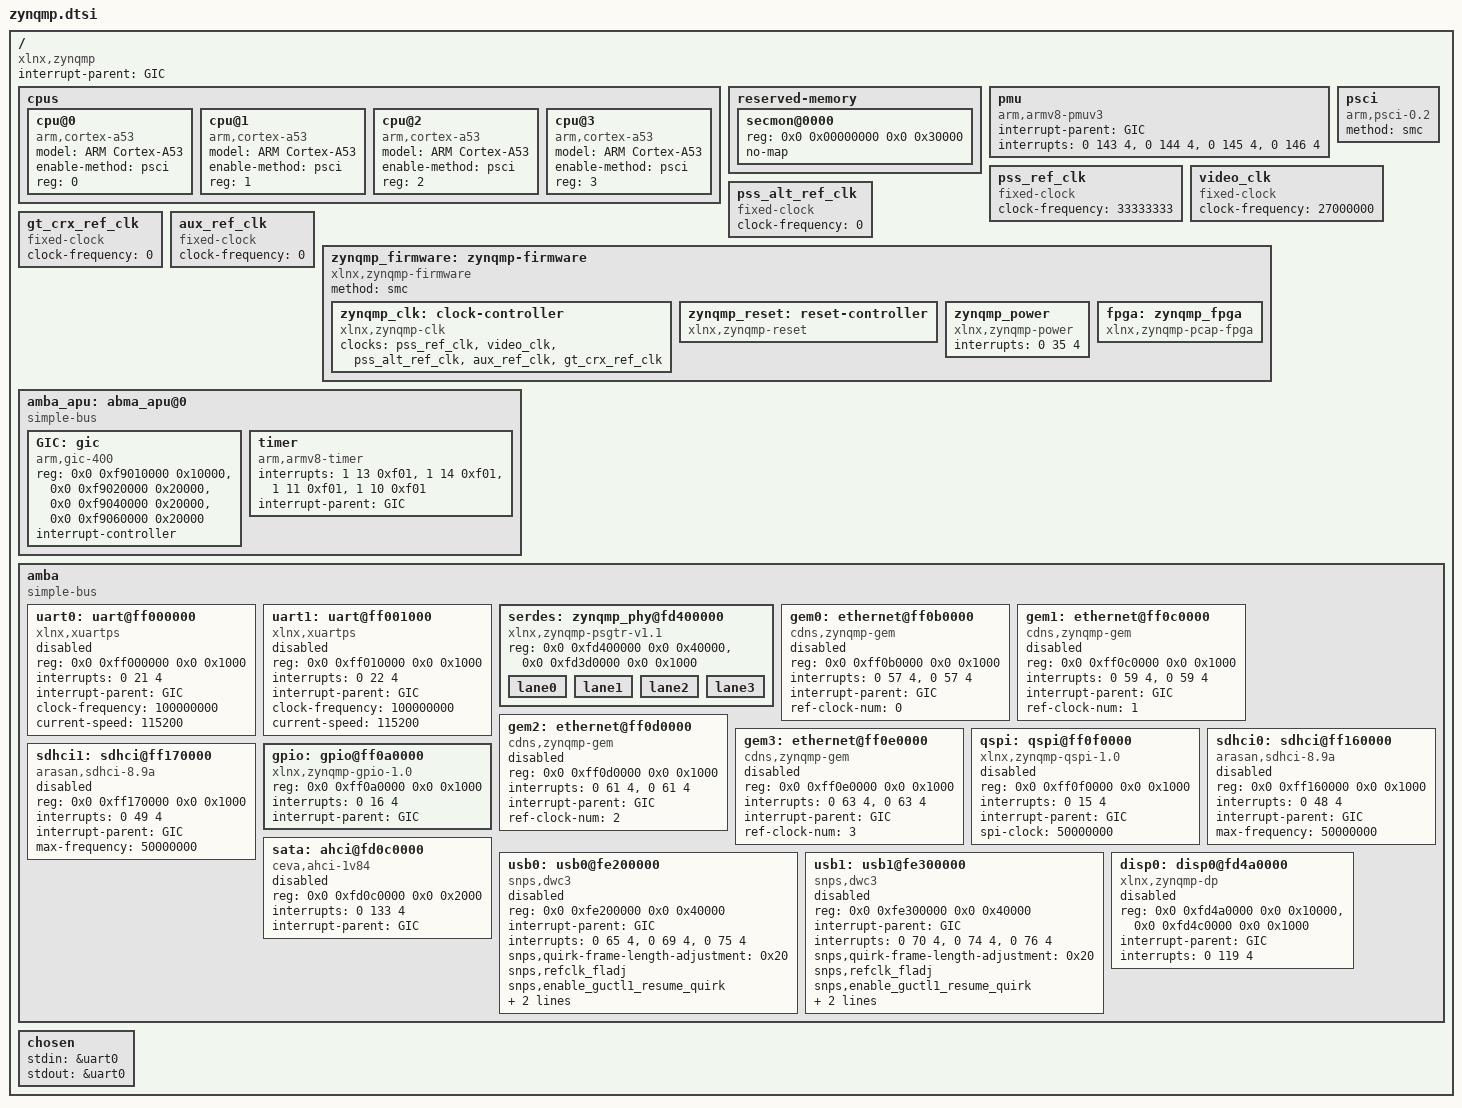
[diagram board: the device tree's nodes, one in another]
/*-
 * Copyright (c) 2018 The FreeBSD Foundation
 * All rights reserved.
 *
 * Redistribution and use in source and binary forms, with or without
 * modification, are permitted provided that the following conditions
 * are met:
 * 1. Redistributions of source code must retain the above copyright
 *    notice, this list of conditions and the following disclaimer.
 * 2. Redistributions in binary form must reproduce the above copyright
 *    notice, this list of conditions and the following disclaimer in the
 *    documentation and/or other materials provided with the distribution.
 *
 * THIS SOFTWARE IS PROVIDED BY THE AUTHOR AND CONTRIBUTORS ``AS IS'' AND
 * ANY EXPRESS OR IMPLIED WARRANTIES, INCLUDING, BUT NOT LIMITED TO, THE
 * IMPLIED WARRANTIES OF MERCHANTABILITY AND FITNESS FOR A PARTICULAR PURPOSE
 * ARE DISCLAIMED. IN NO EVENT SHALL THE AUTHOR OR CONTRIBUTORS BE LIABLE
 * FOR ANY DIRECT, INDIRECT, INCIDENTAL, SPECIAL, EXEMPLARY, OR CONSEQUENTIAL
 * DAMAGES (INCLUDING, BUT NOT LIMITED TO, PROCUREMENT OF SUBSTITUTE GOODS
 * OR SERVICES; LOSS OF USE, DATA, OR PROFITS; OR BUSINESS INTERRUPTION)
 * HOWEVER CAUSED AND ON ANY THEORY OF LIABILITY, WHETHER IN CONTRACT, STRICT
 * LIABILITY, OR TORT (INCLUDING NEGLIGENCE OR OTHERWISE) ARISING IN ANY WAY
 * OUT OF THE USE OF THIS SOFTWARE, EVEN IF ADVISED OF THE POSSIBILITY OF
 * SUCH DAMAGE.
 *
 * $FreeBSD$
 */

/* DTSI file for Xilinx Zynq-UltraScale MPSoC boards. */

/ {
	compatible = "xlnx,zynqmp";
	#address-cells = <2>;
	#size-cells = <2>;
	interrupt-parent = <&GIC>;

	cpus {
		#address-cells = <1>;
		#size-cells = <0>;
		cpu@0 {
			device_type = "cpu";
			compatible = "arm,cortex-a53", "arm,armv8";
			model = "ARM Cortex-A53";
			enable-method = "psci";
			reg = <0>;
		};
		cpu@1 {
			device_type = "cpu";
			compatible = "arm,cortex-a53", "arm,armv8";
			model = "ARM Cortex-A53";
			enable-method = "psci";
			reg = <1>;
		};
		cpu@2 {
			device_type = "cpu";
			compatible = "arm,cortex-a53", "arm,armv8";
			model = "ARM Cortex-A53";
			enable-method = "psci";
			reg = <2>;
		};
		cpu@3 {
			device_type = "cpu";
			compatible = "arm,cortex-a53", "arm,armv8";
			model = "ARM Cortex-A53";
			enable-method = "psci";
			reg = <3>;
		};
	};

	reserved-memory {
		#address-cells = <2>;
		#size-cells = <2>;
		ranges;

		/* 192K reserved for ARM Trusted Firmware (BL31) */
		secmon@0000 {
			reg = <0x0 0x00000000 0x0 0x30000>;
			no-map;
		};
	};

	pmu {
		compatible = "arm,armv8-pmuv3";
		interrupt-parent = <&GIC>;
		interrupts = <0 143 4>, <0 144 4>,
			     <0 145 4>, <0 146 4>;
	};

	psci {
		compatible = "arm,psci-0.2";
		method = "smc";
	};

	// Fixed clocks
	pss_ref_clk: pss_ref_clk {
		compatible = "fixed-clock";
		#clock-cells = <0>;
		clock-frequency = <33333333>; // 33Mhz
	};
	video_clk: video_clk {
		compatible = "fixed-clock";
		#clock-cells = <0>;
		clock-frequency = <27000000>; // 27Mhz
	};
	pss_alt_ref_clk: pss_alt_ref_clk {
		compatible = "fixed-clock";
		#clock-cells = <0>;
		clock-frequency = <0>;
	};
	gt_crx_ref_clk: gt_crx_ref_clk {
		compatible = "fixed-clock";
		#clock-cells = <0>;
		clock-frequency = <0>;
	};
	aux_ref_clk: aux_ref_clk {
		compatible = "fixed-clock";
		#clock-cells = <0>;
		clock-frequency = <0>;
	};




	// firmware { // XXX: we need a general "firmware" node in kernel.

		zynqmp_firmware: zynqmp-firmware {
			compatible = "xlnx,zynqmp-firmware";
			method = "smc";

			zynqmp_clk: clock-controller {
				compatible = "xlnx,zynqmp-clk";
				#clock-cells = <1>;
				clock-names = "pss_ref_clk", "video_clk",
				    "pss_alt_ref_clk", "aux_ref_clk",
				    "gt_crx_ref_clk";
				clocks = <&pss_ref_clk>, <&video_clk>,
				    <&pss_alt_ref_clk>, <&aux_ref_clk>,
				    <&gt_crx_ref_clk>;
			};

			zynqmp_reset: reset-controller {
				compatible = "xlnx,zynqmp-reset";
				#reset-cells = <1>;
			};

			zynqmp_power: zynqmp_power {
				compatible = "xlnx,zynqmp-power";
				interrupts = <0 35 4>;
			};

			fpga: zynqmp_fpga {
				compatible = "xlnx,zynqmp-pcap-fpga";
			};
		};
	// };

	amba_apu: abma_apu@0 {
		compatible = "simple-bus";
		#address-cells = <2>;
		#size-cells = <1>;
		ranges;

		// Interrupt controller
		GIC: gic {
			compatible = "arm,gic-400";
			#interrupt-cells = <3>;
			ranges;
			reg = <0x0 0xf9010000 0x10000>,
			      <0x0 0xf9020000 0x20000>,
			      <0x0 0xf9040000 0x20000>,
			      <0x0 0xf9060000 0x20000>;
			interrupt-controller;
		};

		timer {
			compatible = "arm,armv8-timer"; /* generic_timer.c */
			interrupts = <1 13 0xf01>,
				     <1 14 0xf01>,
				     <1 11 0xf01>,
				     <1 10 0xf01>;
			interrupt-parent = <&GIC>;
		};
	};

	amba: amba {
		compatible = "simple-bus";
		#address-cells = <2>;
		#size-cells = <2>;
		ranges;

		uart0: uart@ff000000 {
			device_type = "serial";
			compatible = "xlnx,xuartps";
			status = "disabled";
			reg = <0x0 0xff000000 0x0 0x1000>;
			interrupts = <0 21 4>;
			interrupt-parent = <&GIC>;
			clock-frequency = <100000000>;
			current-speed = <115200>;
		};

		uart1: uart@ff001000 {
			device_type = "serial";
			compatible = "xlnx,xuartps";
			status = "disabled";
			reg = <0x0 0xff010000 0x0 0x1000>;
			interrupts = <0 22 4>;
			interrupt-parent = <&GIC>;
			clock-frequency = <100000000>;
			current-speed = <115200>;
		};

		serdes: zynqmp_phy@fd400000 {
			compatible = "xlnx,zynqmp-psgtr-v1.1";
			reg = <0x0 0xfd400000 0x0 0x40000>,
				<0x0 0xfd3d0000 0x0 0x1000>;

			lane0: lane0 {
				#phy-cells = <4>;
			};
			lane1: lane1 {
				#phy-cells = <4>;
			};
			lane2: lane2 {
				#phy-cells = <4>;
			};
			lane3: lane3 {
				#phy-cells = <4>;
			};
		};

		gem0: ethernet@ff0b0000 {
			device_type = "network";
			compatible = "cdns,zynqmp-gem", "cdns,gem";
			status = "disabled";
			reg = <0x0 0xff0b0000 0x0 0x1000>;
			interrupts = <0 57 4>, <0 57 4>;
			interrupt-parent = <&GIC>;
			ref-clock-num = <0>;
		};

		gem1: ethernet@ff0c0000 {
			device_type = "network";
			compatible = "cdns,zynqmp-gem", "cdns,gem";
			status = "disabled";
			reg = <0x0 0xff0c0000 0x0 0x1000>;
			interrupts = <0 59 4>, <0 59 4>;
			interrupt-parent = <&GIC>;
			ref-clock-num = <1>;
		};

		gem2: ethernet@ff0d0000 {
			device_type = "network";
			compatible = "cdns,zynqmp-gem", "cdns,gem";
			status = "disabled";
			reg = <0x0 0xff0d0000 0x0 0x1000>;
			interrupts = <0 61 4>, <0 61 4>;
			interrupt-parent = <&GIC>;
			ref-clock-num = <2>;
		};

		gem3: ethernet@ff0e0000 {
			device_type = "network";
			compatible = "cdns,zynqmp-gem", "cdns,gem";
			status = "disabled";
			reg = <0x0 0xff0e0000 0x0 0x1000>;
			interrupts = <0 63 4>, <0 63 4>;
			interrupt-parent = <&GIC>;
			ref-clock-num = <3>;
		};

		qspi: qspi@ff0f0000 {
			compatible = "xlnx,zynqmp-qspi-1.0";
			status = "disabled";
			reg = <0x0 0xff0f0000 0x0 0x1000>;
			interrupts = <0 15 4>;
			interrupt-parent = <&GIC>;
			spi-clock = <50000000>;
		};

		sdhci0: sdhci@ff160000 {
			compatible = "arasan,sdhci-8.9a", "xlnx,zy7_sdhci";
			status = "disabled";
			reg = <0x0 0xff160000 0x0 0x1000>;
			interrupts = <0 48 4>;
			interrupt-parent = <&GIC>;
			max-frequency = <50000000>;
		};

		sdhci1: sdhci@ff170000 {
			compatible = "arasan,sdhci-8.9a", "xlnx,zy7_sdhci";
			status = "disabled";
			reg = <0x0 0xff170000 0x0 0x1000>;
			interrupts = <0 49 4>;
			interrupt-parent = <&GIC>;
			max-frequency = <50000000>;
		};

		gpio: gpio@ff0a0000 {
			compatible = "xlnx,zynqmp-gpio-1.0";
			reg = <0x0 0xff0a0000 0x0 0x1000>;
			interrupts = <0 16 4>;
			interrupt-parent = <&GIC>;
		};

		sata: ahci@fd0c0000 {
			compatible = "ceva,ahci-1v84";
			status = "disabled";
			reg = <0x0 0xfd0c0000 0x0 0x2000>;
			interrupts = <0 133 4>;
			interrupt-parent = <&GIC>;
		};

		usb0: usb0@fe200000 {
			compatible = "snps,dwc3";
			status = "disabled";
			reg = <0x0 0xfe200000 0x0 0x40000>;

			interrupt-parent = <&GIC>;
			interrupts = <0 65 4>, <0 69 4>, <0 75 4>;

			snps,quirk-frame-length-adjustment = <0x20>;
			snps,refclk_fladj;
			snps,enable_guctl1_resume_quirk;
			snps,enable_guctl1_ipd_quirk;
			snps,xhci-stream-quirk;
		};

		usb1: usb1@fe300000 {
			compatible = "snps,dwc3";
			status = "disabled";
			reg = <0x0 0xfe300000 0x0 0x40000>;

			interrupt-parent = <&GIC>;
			interrupts = <0 70 4>, <0 74 4>, <0 76 4>;

			snps,quirk-frame-length-adjustment = <0x20>;
			snps,refclk_fladj;
			snps,enable_guctl1_resume_quirk;
			snps,enable_guctl1_ipd_quirk;
			snps,xhci-stream-quirk;
		};

		disp0: disp0@fd4a0000 {
			compatible = "xlnx,zynqmp-dp";
			status = "disabled";
			reg = <0x0 0xfd4a0000 0x0 0x10000>,
			      <0x0 0xfd4c0000 0x0 0x1000>;
			interrupt-parent = <&GIC>;
			interrupts = <0 119 4>;
		};
	};

	chosen {
		stdin = &uart0;
		stdout = &uart0;
	};
};
